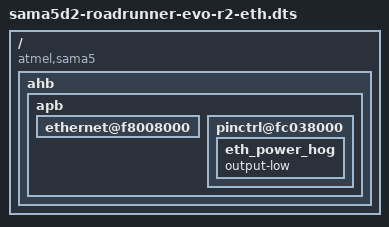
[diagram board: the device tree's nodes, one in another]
/dts-v1/;
/plugin/;

/ {
    fragment@011111_eth {
        target-path = "/";
        __overlay__ {
            compatible = "atmel,sama5", "atmel,sama5d2", "atmel,sama5d2-evo-r2-eth";
            ahb {
                apb {
                    ethernet@f8008000 {
                        status = "okay";
                    };

                    pinctrl@fc038000 {
                       eth_power_hog {
                           output-low;
                       };
                    };
                };
            };
        };
    };
};
